# ATSAM3U4E device description
Architecture: CORTEX-M3; Family: SAM3; Series: SAM3U
Registers are 32-bit, read-write, no defined reset value unless marked. A register's access mark holds for its fields unless they carry their own. Offsets are from the block's base; [hi:lo] are bit positions; {n}, {i} and the like mark numbered series.

## MATRIX — AHB Bus Matrix
Instances: MATRIX 0x400E0200
{0x0+4i} MATRIX_MCFG{i} (i=0..4) — Master Configuration Register {i}
  [2:0] ULBT — Undefined Length Burst Type
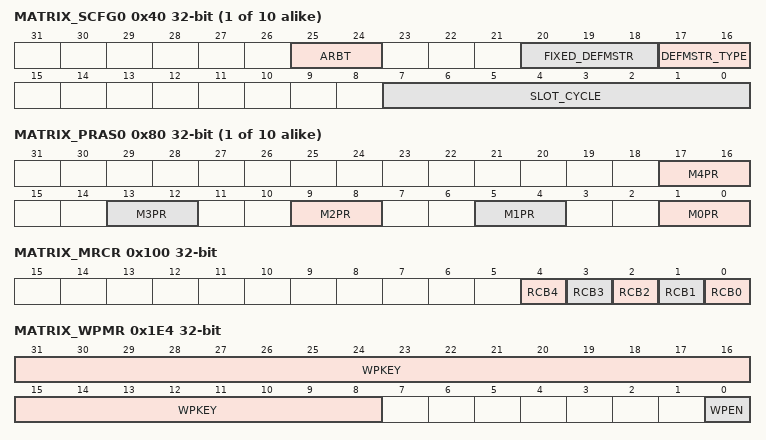
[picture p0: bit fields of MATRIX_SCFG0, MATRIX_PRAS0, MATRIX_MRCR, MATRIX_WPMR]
{0x40+4i} MATRIX_SCFG{i} (i=0..9) — Slave Configuration Register {i}
  [25:24] ARBT — Arbitration Type
  [20:18] FIXED_DEFMSTR — Fixed Default Master
  [17:16] DEFMSTR_TYPE — Default Master Type
  [7:0] SLOT_CYCLE — Maximum Number of Allowed Cycles for a Burst
{0x80+8i} MATRIX_PRAS{i} (i=0..9) — Priority Register A for Slave {i}
  [4n+1:4n] M{n}PR (n=0..4) — Master {n} Priority
0x100 MATRIX_MRCR — Master Remap Control Register
  [n] RCB{n} (n=0..4) — Remap Command Bit for AHB Master {n}
0x1E4 MATRIX_WPMR — Write Protect Mode Register
  [31:8] WPKEY — Write Protect KEY (Write-only)
  [0] WPEN — Write Protect ENable
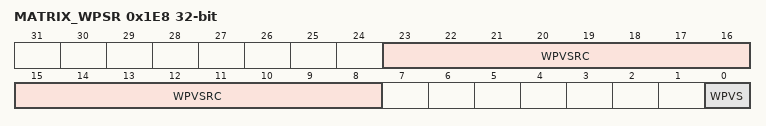
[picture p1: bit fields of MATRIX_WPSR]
0x1E8 MATRIX_WPSR ro — Write Protect Status Register
  [23:8] WPVSRC — Write Protect Violation Source
  [0] WPVS — Write Protect Violation Status

## PDC — Peripheral DMA Controller
0x00 PERIPH_RPR — Receive Pointer Register
  [31:0] RXPTR
0x04 PERIPH_RCR — Receive Counter Register
  [15:0] RXCTR
0x08 PERIPH_TPR — Transmit Pointer Register
  [31:0] TXPTR — Transmit Counter Register
0x0C PERIPH_TCR — Transmit Counter Register
  [15:0] TXCTR
0x10 PERIPH_RNPR — Receive Next Pointer Register
  [31:0] RXNPTR — Receive Next Pointer
0x14 PERIPH_RNCR — Receive Next Counter Register
  [15:0] RXNCTR — Receive Next Counter
0x18 PERIPH_TNPR — Transmit Next Pointer Register
  [31:0] TXNPTR — Transmit Next Pointer
0x1C PERIPH_TNCR — Transmit Next Counter Register
  [15:0] TXNCTR — Transmit Counter Next
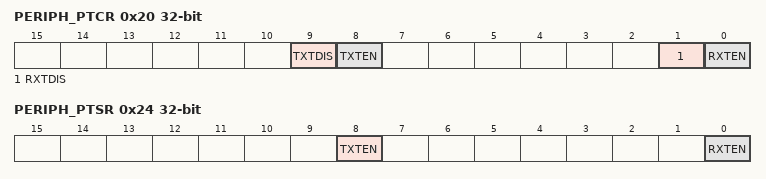
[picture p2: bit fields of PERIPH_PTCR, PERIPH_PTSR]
0x20 PERIPH_PTCR wo — Transfer Control Register
  [9] TXTDIS — Transmitter Transfer Disable
  [8] TXTEN — Transmitter Transfer Enable
  [1] RXTDIS — Receiver Transfer Disable
  [0] RXTEN — Receiver Transfer Enable
0x24 PERIPH_PTSR ro — Transfer Status Register
  [8] TXTEN — Transmitter Transfer Enable
  [0] RXTEN — Receiver Transfer Enable

## RSTC — Reset Controller
Instances: RSTC 0x400E1200
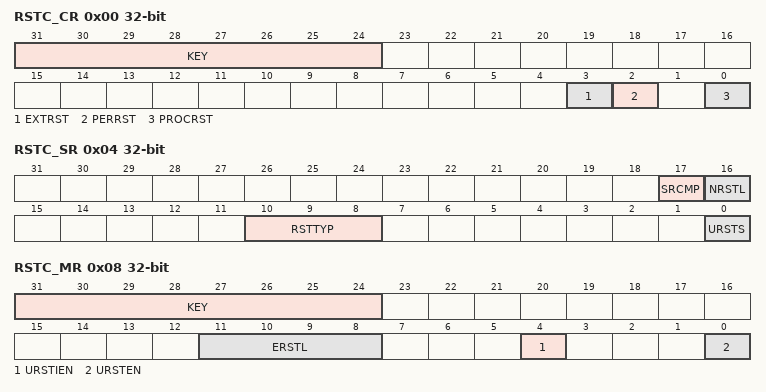
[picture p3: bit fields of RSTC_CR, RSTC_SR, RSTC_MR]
0x00 RSTC_CR wo — Control Register
  [31:24] KEY — Password
  [3] EXTRST — External Reset
  [2] PERRST — Peripheral Reset
  [0] PROCRST — Processor Reset
0x04 RSTC_SR ro — Status Register
  [17] SRCMP — Software Reset Command in Progress
  [16] NRSTL — NRST Pin Level
  [10:8] RSTTYP — Reset Type
  [0] URSTS — User Reset Status
0x08 RSTC_MR — Mode Register
  [31:24] KEY — Password
  [11:8] ERSTL — External Reset Length
  [4] URSTIEN — User Reset Interrupt Enable
  [0] URSTEN — User Reset Enable

## RTT — Real-time Timer
Instances: RTT 0x400E1230
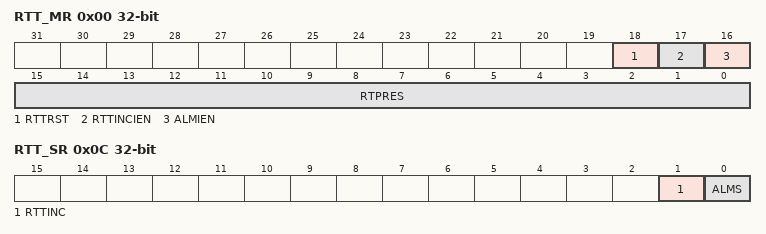
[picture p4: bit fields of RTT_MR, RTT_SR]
0x00 RTT_MR — Mode Register
  [18] RTTRST — Real-time Timer Restart
  [17] RTTINCIEN — Real-time Timer Increment Interrupt Enable
  [16] ALMIEN — Alarm Interrupt Enable
  [15:0] RTPRES — Real-time Timer Prescaler Value
0x04 RTT_AR — Alarm Register
  [31:0] ALMV — Alarm Value
0x08 RTT_VR ro — Value Register
  [31:0] CRTV — Current Real-time Value
0x0C RTT_SR ro — Status Register
  [1] RTTINC — Real-time Timer Increment
  [0] ALMS — Real-time Alarm Status

## SPI — Serial Peripheral Interface
Instances: SPI 0x40008000
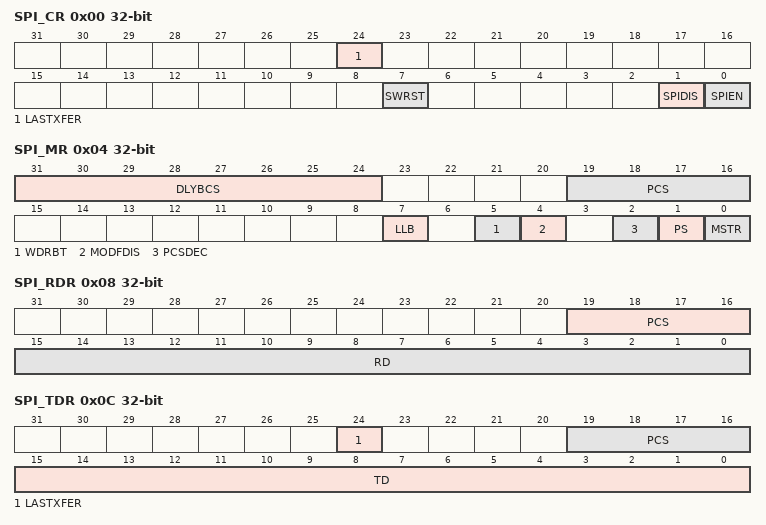
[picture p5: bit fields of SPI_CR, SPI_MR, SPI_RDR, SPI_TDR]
0x00 SPI_CR wo — Control Register
  [24] LASTXFER — Last Transfer
  [7] SWRST — SPI Software Reset
  [1] SPIDIS — SPI Disable
  [0] SPIEN — SPI Enable
0x04 SPI_MR — Mode Register
  [31:24] DLYBCS — Delay Between Chip Selects
  [19:16] PCS — Peripheral Chip Select
  [7] LLB — Local Loopback Enable
  [5] WDRBT — Wait Data Read Before Transfer
  [4] MODFDIS — Mode Fault Detection
  [2] PCSDEC — Chip Select Decode
  [1] PS — Peripheral Select
  [0] MSTR — Master/Slave Mode
0x08 SPI_RDR ro — Receive Data Register
  [19:16] PCS — Peripheral Chip Select
  [15:0] RD — Receive Data
0x0C SPI_TDR wo — Transmit Data Register
  [24] LASTXFER — Last Transfer
  [19:16] PCS — Peripheral Chip Select
  [15:0] TD — Transmit Data
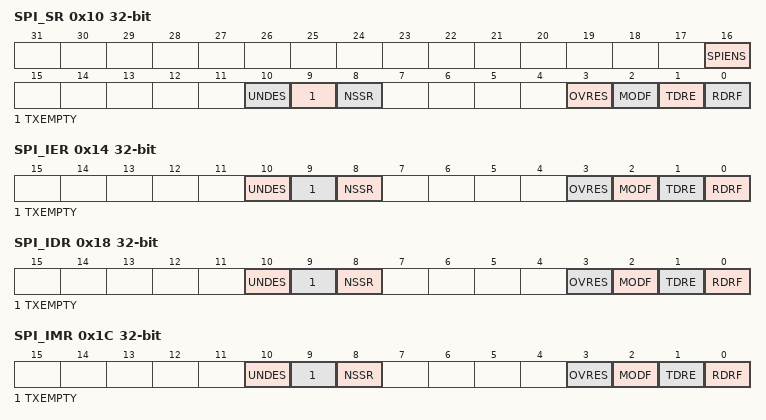
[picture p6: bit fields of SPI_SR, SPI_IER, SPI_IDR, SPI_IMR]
0x10 SPI_SR ro — Status Register
  [16] SPIENS — SPI Enable Status
  [10] UNDES — Underrun Error Status (Slave Mode Only)
  [9] TXEMPTY — Transmission Registers Empty
  [8] NSSR — NSS Rising
  [3] OVRES — Overrun Error Status
  [2] MODF — Mode Fault Error
  [1] TDRE — Transmit Data Register Empty
  [0] RDRF — Receive Data Register Full
0x14 SPI_IER wo — Interrupt Enable Register
  [10] UNDES — Underrun Error Interrupt Enable
  [9] TXEMPTY — Transmission Registers Empty Enable
  [8] NSSR — NSS Rising Interrupt Enable
  [3] OVRES — Overrun Error Interrupt Enable
  [2] MODF — Mode Fault Error Interrupt Enable
  [1] TDRE — SPI Transmit Data Register Empty Interrupt Enable
  [0] RDRF — Receive Data Register Full Interrupt Enable
0x18 SPI_IDR wo — Interrupt Disable Register
  [10] UNDES — Underrun Error Interrupt Disable
  [9] TXEMPTY — Transmission Registers Empty Disable
  [8] NSSR — NSS Rising Interrupt Disable
  [3] OVRES — Overrun Error Interrupt Disable
  [2] MODF — Mode Fault Error Interrupt Disable
  [1] TDRE — SPI Transmit Data Register Empty Interrupt Disable
  [0] RDRF — Receive Data Register Full Interrupt Disable
0x1C SPI_IMR ro — Interrupt Mask Register
  [10] UNDES — Underrun Error Interrupt Mask
  [9] TXEMPTY — Transmission Registers Empty Mask
  [8] NSSR — NSS Rising Interrupt Mask
  [3] OVRES — Overrun Error Interrupt Mask
  [2] MODF — Mode Fault Error Interrupt Mask
  [1] TDRE — SPI Transmit Data Register Empty Interrupt Mask
  [0] RDRF — Receive Data Register Full Interrupt Mask
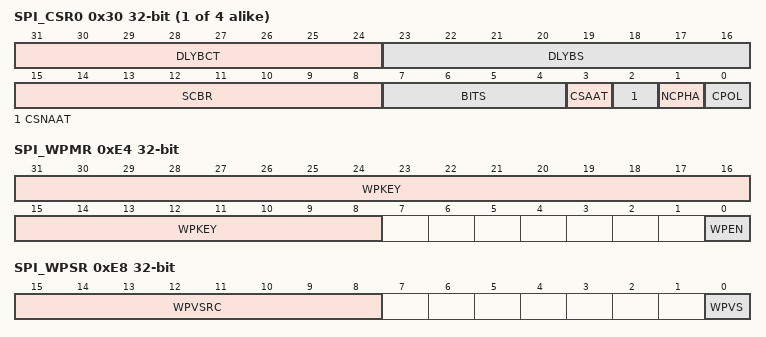
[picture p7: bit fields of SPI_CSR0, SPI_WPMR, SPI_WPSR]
{0x30+4i} SPI_CSR{i} (i=0..3) — Chip Select Register {i}
  [31:24] DLYBCT — Delay Between Consecutive Transfers
  [23:16] DLYBS — Delay Before SPCK
  [15:8] SCBR — Serial Clock Baud Rate
  [7:4] BITS — Bits Per Transfer
    {v}=_{v+8}_BIT ({v+8} bits for transfer) (v=0..8)
  [3] CSAAT — Chip Select Active After Transfer
  [2] CSNAAT — Chip Select Not Active After Transfer (Ignored if CSAAT = 1)
  [1] NCPHA — Clock Phase
  [0] CPOL — Clock Polarity
0xE4 SPI_WPMR — Write Protection Control Register
  [31:8] WPKEY — Write Protect Key
    0x535049=PASSWD (Writing any other value in this field aborts the write operation of the WPEN bit.Always reads as 0.)
  [0] WPEN — Write Protect Enable
0xE8 SPI_WPSR ro — Write Protection Status Register
  [15:8] WPVSRC — Write Protection Violation Source
  [0] WPVS — Write Protection Violation Status
